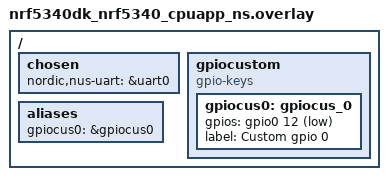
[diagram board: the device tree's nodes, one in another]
/ {
	chosen {
		nordic,nus-uart = &uart0;
	};
};

/ {
    gpiocustom {
        compatible = "gpio-keys";
        gpiocus0: gpiocus_0 {
            gpios = <&gpio0 12 GPIO_ACTIVE_LOW>;
            label = "Custom gpio 0";
        };
    };
    aliases {
        gpiocus0 = &gpiocus0;
    };
};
